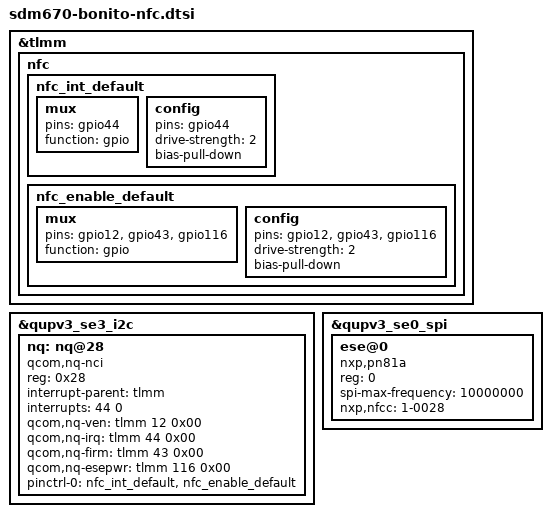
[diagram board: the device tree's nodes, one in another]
&tlmm {
	nfc {
		/* define the real stuff */
		nfc_int_default: nfc_int_default {
			/* default state */
			mux {
				/* GPIO 44 NFC Read Interrupt */
				pins = "gpio44";
				function = "gpio";
			};

			config {
				pins = "gpio44";
				drive-strength = <2>; /* 2 MA */
				bias-pull-down;
			};
		};

		nfc_enable_default: nfc_enable_default {
			/* default state */
			mux {
				/* 12: NFC ENABLE, 116: NFC_SE_PWR_REQ */
				/* 43: NFC_FW_DL_REQ_FROM_HOST */
				pins = "gpio12", "gpio43", "gpio116";
				function = "gpio";
			};

			config {
				pins = "gpio12", "gpio43", "gpio116";
				drive-strength = <2>; /* 2 MA */
				bias-pull-down;
			};
		};
	};
};

&qupv3_se3_i2c {
	status = "okay";
	nq: nq@28 {
		status = "okay";
		compatible = "qcom,nq-nci";
		reg = <0x28>;
		interrupt-parent = <&tlmm>;
		interrupt-names = "nfc_irq";
		interrupts = <44 0>;
		qcom,nq-ven = <&tlmm 12 0x00>;
		qcom,nq-irq = <&tlmm 44 0x00>;
		qcom,nq-firm = <&tlmm 43 0x00>;
		qcom,nq-esepwr = <&tlmm 116 0x00>;
		pinctrl-names = "default";
		pinctrl-0 = <&nfc_int_default &nfc_enable_default>;
	};
};

&qupv3_se0_spi {
	status = "ok";

	ese@0 {
		compatible = "nxp,pn81a";
		reg = <0>;
		spi-max-frequency = <10000000>;
		/* i2c NFC device handles eSE power:
		 * i2c_1, reg 0x28
		 */
		nxp,nfcc = "1-0028";
	};
};
